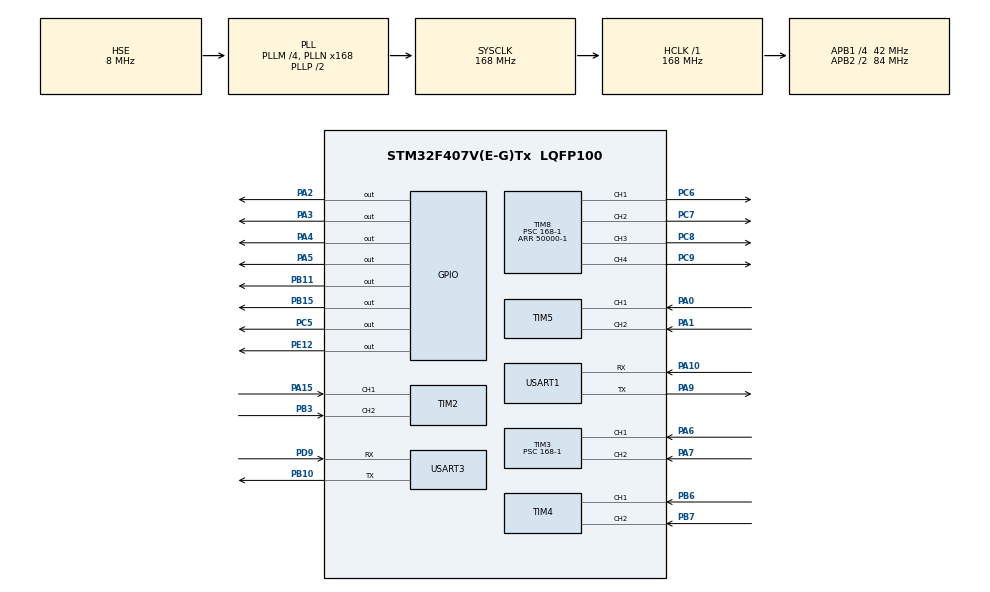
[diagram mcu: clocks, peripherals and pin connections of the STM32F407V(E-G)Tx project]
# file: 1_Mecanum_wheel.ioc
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Mcu.Family=STM32F4
Mcu.Name=STM32F407V(E-G)Tx
Mcu.Package=LQFP100
NVIC.PriorityGroup=NVIC_PRIORITYGROUP_4
NVIC.TIM2_IRQn=true\:0\:0\:false\:false\:true\:true\:true\:true
NVIC.TIM3_IRQn=true\:0\:0\:false\:false\:true\:true\:true\:true
NVIC.TIM4_IRQn=true\:0\:0\:false\:false\:true\:true\:true\:true
NVIC.TIM5_IRQn=true\:0\:0\:false\:false\:true\:true\:true\:true
NVIC.TIM6_DAC_IRQn=true\:0\:0\:false\:false\:true\:true\:true\:true
PA0-WKUP.Signal=S_TIM5_CH1
PA1.Signal=S_TIM5_CH2
PA10.Mode=Asynchronous
PA10.Signal=USART1_RX
PA13.Mode=Serial_Wire
PA13.Signal=SYS_JTMS-SWDIO
PA14.Mode=Serial_Wire
PA14.Signal=SYS_JTCK-SWCLK
PA15.Signal=S_TIM2_CH1_ETR
PA2.Signal=GPIO_Output
PA3.Signal=GPIO_Output
PA4.Signal=GPIO_Output
PA5.Signal=GPIO_Output
PA6.Signal=S_TIM3_CH1
PA7.Signal=S_TIM3_CH2
PA9.Mode=Asynchronous
PA9.Signal=USART1_TX
PB10.Mode=Asynchronous
PB10.Signal=USART3_TX
PB11.Signal=GPIO_Output
PB15.Signal=GPIO_Output
PB3.Signal=S_TIM2_CH2
PB6.Signal=S_TIM4_CH1
PB7.Signal=S_TIM4_CH2
PC5.Signal=GPIO_Output
PC6.Signal=S_TIM8_CH1
PC7.Signal=S_TIM8_CH2
PC8.Signal=S_TIM8_CH3
PC9.Signal=S_TIM8_CH4
PD9.Mode=Asynchronous
PD9.Signal=USART3_RX
PE12.Signal=GPIO_Output
PH0-OSC_IN.Mode=HSE-External-Oscillator
PH0-OSC_IN.Signal=RCC_OSC_IN
PH1-OSC_OUT.Mode=HSE-External-Oscillator
PH1-OSC_OUT.Signal=RCC_OSC_OUT
ProjectManager.HeapSize=0x200
ProjectManager.StackSize=0x400
ProjectManager.TargetToolchain=Makefile
RCC.48MHZClocksFreq_Value=84000000
RCC.AHBFreq_Value=168000000
RCC.APB1CLKDivider=RCC_HCLK_DIV4
RCC.APB1Freq_Value=42000000
RCC.APB1TimFreq_Value=84000000
RCC.APB2CLKDivider=RCC_HCLK_DIV2
RCC.APB2Freq_Value=84000000
RCC.APB2TimFreq_Value=168000000
RCC.CortexFreq_Value=168000000
RCC.HCLKFreq_Value=168000000
RCC.HSE_VALUE=8000000
RCC.HSI_VALUE=16000000
RCC.LSE_VALUE=32768
RCC.PLLM=4
RCC.PLLN=168
RCC.PLLSourceVirtual=RCC_PLLSOURCE_HSE
RCC.SYSCLKFreq_VALUE=168000000
RCC.SYSCLKSource=RCC_SYSCLKSOURCE_PLLCLK
RCC.VCOOutputFreq_Value=336000000
SH.S_TIM2_CH1_ETR.0=TIM2_CH1,Encoder_Interface
SH.S_TIM2_CH2.0=TIM2_CH2,Encoder_Interface
SH.S_TIM3_CH1.0=TIM3_CH1,Encoder_Interface
SH.S_TIM3_CH2.0=TIM3_CH2,Encoder_Interface
SH.S_TIM4_CH1.0=TIM4_CH1,Encoder_Interface
SH.S_TIM4_CH2.0=TIM4_CH2,Encoder_Interface
SH.S_TIM5_CH1.0=TIM5_CH1,Encoder_Interface
SH.S_TIM5_CH2.0=TIM5_CH2,Encoder_Interface
SH.S_TIM8_CH1.0=TIM8_CH1,PWM Generation1 CH1
SH.S_TIM8_CH2.0=TIM8_CH2,PWM Generation2 CH2
SH.S_TIM8_CH3.0=TIM8_CH3,PWM Generation3 CH3
SH.S_TIM8_CH4.0=TIM8_CH4,PWM Generation4 CH4
TIM2.EncoderMode=TIM_ENCODERMODE_TI12
TIM3.EncoderMode=TIM_ENCODERMODE_TI12
TIM3.Period=50000-1
TIM3.Prescaler=168-1
TIM4.EncoderMode=TIM_ENCODERMODE_TI12
TIM5.EncoderMode=TIM_ENCODERMODE_TI12
TIM6.Period=5000-1
TIM6.Prescaler=168-1
TIM8.Channel-PWM\ Generation1\ CH1=TIM_CHANNEL_1
TIM8.Channel-PWM\ Generation2\ CH2=TIM_CHANNEL_2
TIM8.Channel-PWM\ Generation3\ CH3=TIM_CHANNEL_3
TIM8.Channel-PWM\ Generation4\ CH4=TIM_CHANNEL_4
TIM8.Period=50000-1
TIM8.Prescaler=168-1
USART1.VirtualMode=VM_ASYNC
USART3.VirtualMode=VM_ASYNC
VP_TIM6_VS_ClockSourceINT.Mode=Enable_Timer
VP_TIM8_VS_ClockSourceINT.Mode=Internal
board=custom

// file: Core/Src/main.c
/* USER CODE BEGIN Header */
/**
 ******************************************************************************
 * @file           : main.c
 * @brief          : Main program body
 ******************************************************************************
 * @attention
 *
 * Copyright (c) 2023 STMicroelectronics.
 * All rights reserved.
 *
 * This software is licensed under terms that can be found in the LICENSE file
 * in the root directory of this software component.
 * If no LICENSE file comes with this software, it is provided AS-IS.
 *
 ******************************************************************************
 */
/* USER CODE END Header */
#include "main.h"
#include "tim.h"
#include "usart.h"
#include "gpio.h"

/* USER CODE BEGIN Includes */
#include "motor.h"
#include <stdio.h>
/* USER CODE END Includes */

void SystemClock_Config(void);

int main(void)
{

    /* MCU Configuration--------------------------------------------------------*/

    /* Reset of all peripherals, Initializes the Flash interface and the Systick. */
    HAL_Init();

    /* Configure the system clock */
    SystemClock_Config();

    /* Initialize all configured peripherals */
    MX_GPIO_Init();
    MX_TIM3_Init();
    MX_TIM4_Init();
    MX_TIM2_Init();
    MX_TIM5_Init();
    MX_TIM6_Init();
    MX_TIM8_Init();
    MX_USART1_UART_Init();
    MX_USART3_UART_Init();
    /* USER CODE BEGIN 2 */
    Motor_Init(&motor1, 1, 60, 10, 0.1);
    Motor_Init(&motor2, 2, 60, 10, 0.1);
    Motor_Init(&motor3, 3, 60, 10, 0.1);
    Motor_Init(&motor4, 4, 60, 10, 0.1);
    Motor_Start(&motor1);
    Motor_Speed_Set(&motor1, 200);
    /* USER CODE END 2 */

    /* Infinite loop */
    while (1) {

        /* USER CODE BEGIN 3 */
        // Motor_Speed_Set(&motor1,200);
        printf("%.2f\r\n", motor1.pid.Error);
    }
    /* USER CODE END 3 */
}

void SystemClock_Config(void)
{
    RCC_OscInitTypeDef RCC_OscInitStruct = {0};
    RCC_ClkInitTypeDef RCC_ClkInitStruct = {0};

    /** Configure the main internal regulator output voltage
     */
    __HAL_RCC_PWR_CLK_ENABLE();
    __HAL_PWR_VOLTAGESCALING_CONFIG(PWR_REGULATOR_VOLTAGE_SCALE1);

    /** Initializes the RCC Oscillators according to the specified parameters
     * in the RCC_OscInitTypeDef structure.
     */
    RCC_OscInitStruct.OscillatorType = RCC_OSCILLATORTYPE_HSE;
    RCC_OscInitStruct.HSEState       = RCC_HSE_ON;
    RCC_OscInitStruct.PLL.PLLState   = RCC_PLL_ON;
    RCC_OscInitStruct.PLL.PLLSource  = RCC_PLLSOURCE_HSE;
    RCC_OscInitStruct.PLL.PLLM       = 4;
    RCC_OscInitStruct.PLL.PLLN       = 168;
    RCC_OscInitStruct.PLL.PLLP       = RCC_PLLP_DIV2;
    RCC_OscInitStruct.PLL.PLLQ       = 4;
    if (HAL_RCC_OscConfig(&RCC_OscInitStruct) != HAL_OK) {
        Error_Handler();
    }

    /** Initializes the CPU, AHB and APB buses clocks
     */
    RCC_ClkInitStruct.ClockType      = RCC_CLOCKTYPE_HCLK | RCC_CLOCKTYPE_SYSCLK | RCC_CLOCKTYPE_PCLK1 | RCC_CLOCKTYPE_PCLK2;
    RCC_ClkInitStruct.SYSCLKSource   = RCC_SYSCLKSOURCE_PLLCLK;
    RCC_ClkInitStruct.AHBCLKDivider  = RCC_SYSCLK_DIV1;
    RCC_ClkInitStruct.APB1CLKDivider = RCC_HCLK_DIV4;
    RCC_ClkInitStruct.APB2CLKDivider = RCC_HCLK_DIV2;

    if (HAL_RCC_ClockConfig(&RCC_ClkInitStruct, FLASH_LATENCY_5) != HAL_OK) {
        Error_Handler();
    }
}

void Error_Handler(void)
{
    __disable_irq();
    while (1) {
    }
}
